# EFR32BG29B230F1024CM40 register map
Vendor: Silicon Labs; Series: EFR32; File version: C
Registers are 32-bit, read-write, reset 0x0 unless marked. A register's access mark holds for its fields unless they carry their own. Offsets are from the block's base; [hi:lo] are bit positions; {n}, {i} and the like mark numbered series; 'fields as' and 'values as' point back to an identical list.

## DCDC_NS — DCDC_NS Registers
Base 0x50094000
Same registers: DCDC_S 0x40094000
0x00 IPVERSION ro reset 0x6
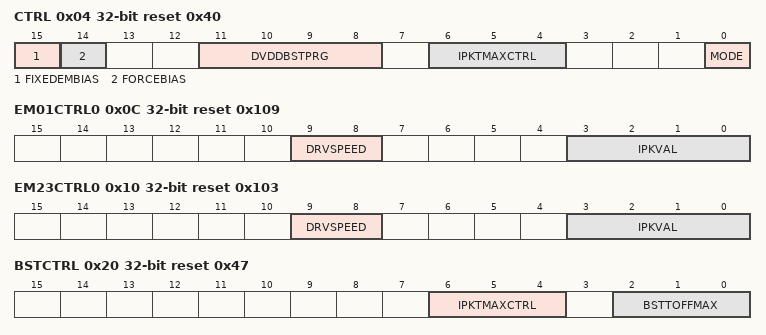
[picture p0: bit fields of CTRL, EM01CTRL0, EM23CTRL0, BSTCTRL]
0x04 CTRL reset 0x40 — Control
  [15] FIXEDEMBIAS — Force EM2 config settings
  [14] FORCEBIAS — Force Comparators to be biased
  [11:8] DVDDBSTPRG — BOOST DCDC output control
    0=BOOST_1V8; 1=BOOST_1V9; 2=BOOST_2V; {v}=BOOST_2V{v-2} (v=3..6)
  [6:4] IPKTMAXCTRL — Peak Current Timeout Control
    0=OFF (Ton_max disabled); 1=TMAX_0P35us (0.35us); 2=TMAX_0P63us (0.63us); 3=TMAX_0P91us (0.91us); 4=TMAX_1P19us (1.19us); 5=TMAX_1P47us (1.47us); 6=TMAX_1P75us (1.75us); 7=TMAX_2P03us (2.03us)
  [0] MODE — DCDC/Bypass Mode Control
    0=BYPASS (DCDC is OFF, bypass switch is enabled); 1=DCDCREGULATION (Request DCDC regulation, bypass switch disabled)
0x0C EM01CTRL0 reset 0x109 — EM01 Configurations
  [9:8] DRVSPEED — EM01 Drive Speed Setting
    1=DEFAULT_SETTING (Recommended for use for best efficiency and low EMI)
  [3:0] IPKVAL — EM01 Peak Current Setting
    3=Load36mA (Ipeak = 90mA, Iload = 36mA); 4=Load40mA (Ipeak = 100mA, Iload = 40mA); 5=Load44mA (Ipeak = 110mA, Iload = 44mA); 6=Load48mA (Ipeak = 120mA, Iload = 48mA); 7=Load52mA (Ipeak = 130mA, Iload = 52mA); 8=Load56mA (Ipeak = 140mA, Iload = 56mA); 9=Load60mA (Ipeak = 150mA, Iload = 60mA)
0x10 EM23CTRL0 reset 0x103 — EM23 Configurations
  [9:8] DRVSPEED — EM23 Drive Speed Setting
    values as EM01CTRL0.DRVSPEED
  [3:0] IPKVAL — EM23 Peak Current Setting
    3=Load5mA (Ipeak = 90mA, Iload = 5 mA); 9=Load10mA (Ipeak = 150mA, Iload = 10 mA)
0x20 BSTCTRL reset 0x47 — Boost Control Register
  [6:4] IPKTMAXCTRL — Ton_max timeout control
    values as CTRL.IPKTMAXCTRL
  [2:0] BSTTOFFMAX — Toff_max timeout control
    0=OFF (Toff_max disabled); 1=TMAX_0P35us (0.35us); 2=TMAX_0P63us (0.63us); 3=TMAX_0P91us (0.91us); 4=TMAX_1P19us (1.19us); 5=TMAX_1P47us (1.47us); 6=TMAX_1P75us (1.75us); 7=TMAX_2P03us (2.03us)
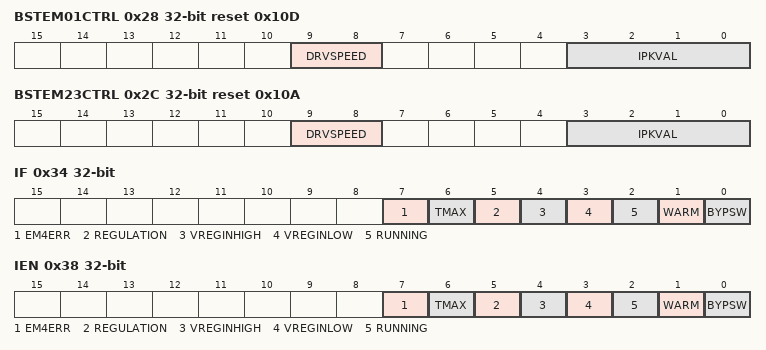
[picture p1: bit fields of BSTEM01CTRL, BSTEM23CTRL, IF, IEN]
0x28 BSTEM01CTRL reset 0x10D — Boost cfg EM01 ctrl
  [9:8] DRVSPEED — EM01 Drive Speed Setting
    values as EM01CTRL0.DRVSPEED
  [3:0] IPKVAL — EM01 Peak Current Setting
    4=Load10mA (Ipeak = 90mA, Iload = 10 mA); 5=Load11mA (Ipeak = 100mA, Iload = 11.7 mA); 6=Load13mA (Ipeak = 110mA, Iload = 13.3 mA); 7=Load15mA (Ipeak = 120mA, Iload = 15 mA); 8=Load16mA (Ipeak = 130mA, Iload = 16.7 mA); 9=Load18mA (Ipeak = 140mA, Iload = 18.3 mA); 10=Load20mA (Ipeak = 150mA, Iload = 20 mA); 11=Load21mA (Ipeak = 160mA, Iload = 21.7 mA); 12=Load23mA (Ipeak = 170mA, Iload = 23.3 mA); 13=Load25mA (Ipeak = 180mA, Iload = 25 mA); 14=Load26mA (Ipeak = 190mA, Iload = 26.7 mA)
0x2C BSTEM23CTRL reset 0x10A — Boost cfg EM23 ctrl
  [9:8] DRVSPEED — EM23 Drive Speed Setting
    values as EM01CTRL0.DRVSPEED
  [3:0] IPKVAL — EM23 Peak Current Setting
    4=Load5mA (Ipeak = 90mA, Iload = 5 mA); 10=Load10mA (Ipeak = 150mA, Iload = 10 mA)
0x34 IF — Interrupt Flags
  [7] EM4ERR — EM4 Entry Request Error
  [6] TMAX — Buck Max Ton/Boost Max Toff reached
  [5] REGULATION — DCDC in regulation
  [4] VREGINHIGH — VREGVDD above threshold
  [3] VREGINLOW — VREGVDD below threshold
  [2] RUNNING — DCDC Running
  [1] WARM — DCDC Warmup Time Done
  [0] BYPSW — Bypass Switch Enabled
0x38 IEN — Interrupt Enable
  [7] EM4ERR — EM4 Entry Req Interrupt Enable
  [6] TMAX — Ton_max Timeout Interrupt Enable
  [5] REGULATION — DCDC in Regulation Interrupt Enable
  [4] VREGINHIGH — VREGVDD above threshold Interrupt Enable
  [3] VREGINLOW — VREGVDD below threshold Interrupt Enable
  [2] RUNNING — DCDC Running Interrupt Enable
  [1] WARM — DCDC Warmup Time Done Interrupt Enable
  [0] BYPSW — Bypass Switch Enabled Interrupt Enable
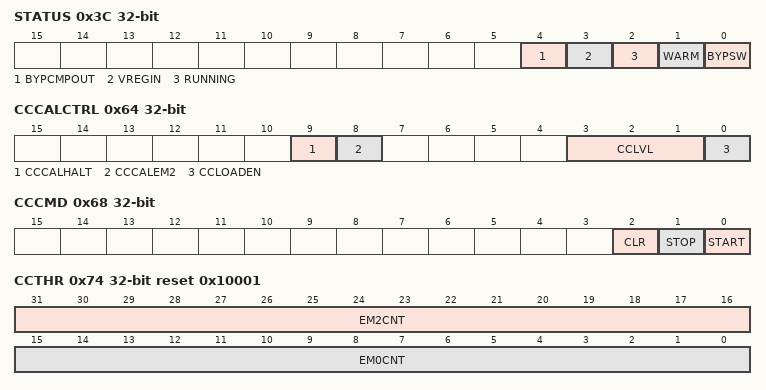
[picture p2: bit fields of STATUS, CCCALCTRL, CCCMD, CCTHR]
0x3C STATUS ro — DCDC Status Register
  [4] BYPCMPOUT — Bypass Comparator Output
  [3] VREGIN — VREGVDD comparator status
  [2] RUNNING — DCDC is running
  [1] WARM — DCDC Warmup Done
  [0] BYPSW — Bypass Switch is currently enabled
0x40 SYNCBUSY ro — Syncbusy Status Register
  [0] SYNCBUSY — Combined Sync Busy Status
0x60 CCCTRL — Coulomb Counter Control Register
  [0] CCEN — Coulomb Counter Enable
0x64 CCCALCTRL — Coulomb Counter Calibration Control
  [9] CCCALHALT — CC Calibration Halt Req
  [8] CCCALEM2 — CC Calibrate EM2
  [3:1] CCLVL — Load Current Level
    0=LOAD0 (Nominal 0.25mA); 1=LOAD1 (Nominal 0.50mA); 2=LOAD2 (Nominal 1.00mA); 3=LOAD3 (Nominal 1.50mA); 4=LOAD4 (Nominal 2.00mA); 5=LOAD5 (Nominal 4.00mA); 6=LOAD6 (Nominal 6.00mA); 7=LOAD7 (Nominal 8.00mA)
  [0] CCLOADEN — CC Load Circuit Enable
0x68 CCCMD wo — Coulomb Counter Command Register
  [2] CLR — Clear CC
  [1] STOP — Stop CC
  [0] START — Start CC
0x6C CCEM0CNT ro — Coulomb Counter EM0 Count Value
  [31:0] CCCNT
0x70 CCEM2CNT ro — Coulomb Counter EM2 Count Value
  [31:0] CCCNT
0x74 CCTHR reset 0x10001 — Coulomb Counter Threshold Reg
  [31:16] EM2CNT — Coulomb Counter EM2 Threshold
  [15:0] EM0CNT — Coulomb Counter EM0 Threshold
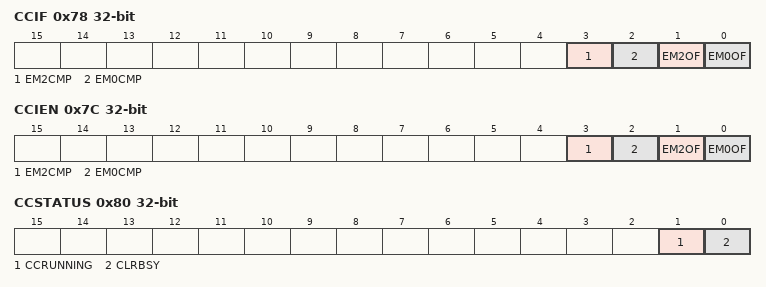
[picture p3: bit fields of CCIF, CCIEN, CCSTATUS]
0x78 CCIF — Coulomb Counter Interrupt Flag
  [3] EM2CMP — EM2 Counter Compare Match
  [2] EM0CMP — EM0 Counter Compare Match
  [1] EM2OF — EM2 Counter Overflow
  [0] EM0OF — EM0 Counter Overflow
0x7C CCIEN — Coulomb Counter Interrupt Enable
  [3] EM2CMP — Clmb Cntr EM2 Cmp Match Interrupt Enable
  [2] EM0CMP — Clmb Cntr EM0 Cmp Match Interrupt Enable
  [1] EM2OF — Clmb Cntr EM2 Overflow Interrupt Enable
  [0] EM0OF — Clmb Cntr EM0 Overflow Interrupt Enable
0x80 CCSTATUS ro — Coulomb Counter Status
  [1] CCRUNNING — Coulomb Counter Running
  [0] CLRBSY — Coulomb Counter Clear Busy
0x90 LOCK wo
  [15:0] LOCKKEY — Configuration Lock Key
    0xABCD=UNLOCKKEY (Value to write to unlock)
0x94 LOCKSTATUS ro
  [0] LOCK — Lock Status
    0=UNLOCKED (Unlocked State); 1=LOCKED (LOCKED STATE)
